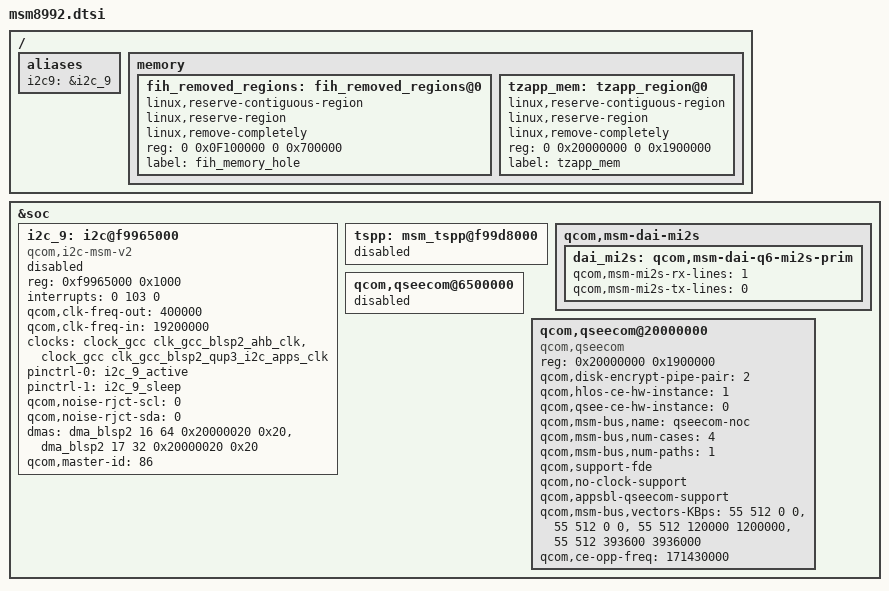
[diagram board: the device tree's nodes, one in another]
/* Copyright (c) 2013-2016, The Linux Foundation. All rights reserved.
 *
 * This program is free software; you can redistribute it and/or modify
 * it under the terms of the GNU General Public License version 2 and
 * only version 2 as published by the Free Software Foundation.
 *
 * This program is distributed in the hope that it will be useful,
 * but WITHOUT ANY WARRANTY; without even the implied warranty of
 * MERCHANTABILITY or FITNESS FOR A PARTICULAR PURPOSE.  See the
 * GNU General Public License for more details.
 */

/ {
	aliases {
		i2c9 = &i2c_9;
	};

	memory {
		fih_removed_regions: fih_removed_regions@0 {
			linux,reserve-contiguous-region;
			linux,reserve-region;
			linux,remove-completely;
			reg = <0 0x0F100000 0 0x700000>;
			label = "fih_memory_hole";
		};

		tzapp_mem: tzapp_region@0 {
			linux,reserve-contiguous-region;
			linux,reserve-region;
			linux,remove-completely;
			reg = <0 0x20000000 0 0x1900000>;
			label = "tzapp_mem";
		};
	};
};

&soc {
	i2c_9: i2c@f9965000 { /* BLSP9 QUP2 */
		compatible = "qcom,i2c-msm-v2";
		#address-cells = <1>;
		#size-cells = <0>;
		status = "disabled";
		reg-names = "qup_phys_addr";
		reg = <0xf9965000 0x1000>;
		interrupt-names = "qup_irq";
		interrupts = <0 103 0>;
		qcom,clk-freq-out = <400000>;
		qcom,clk-freq-in  = <19200000>;
		clock-names = "iface_clk", "core_clk";
		clocks = <&clock_gcc clk_gcc_blsp2_ahb_clk>,
			 <&clock_gcc clk_gcc_blsp2_qup3_i2c_apps_clk>;

		pinctrl-names = "i2c_active", "i2c_sleep";
		pinctrl-0 = <&i2c_9_active>;
		pinctrl-1 = <&i2c_9_sleep>;
		qcom,noise-rjct-scl = <0>;
		qcom,noise-rjct-sda = <0>;
		dmas = <&dma_blsp2 16 64 0x20000020 0x20>,
			<&dma_blsp2 17 32 0x20000020 0x20>;
		dma-names = "tx", "rx";
		qcom,master-id = <86>;
	};

	tspp: msm_tspp@f99d8000 {
		status = "disabled";
	};

	qcom,msm-dai-mi2s {
		dai_mi2s: qcom,msm-dai-q6-mi2s-prim {
			qcom,msm-mi2s-rx-lines = <1>;
			qcom,msm-mi2s-tx-lines = <0>;
		};
	};

	qcom,qseecom@6500000 {
		status = "disabled";
	};

	qcom,qseecom@20000000 {
		compatible = "qcom,qseecom";
		reg = <0x20000000 0x1900000>;
		reg-names = "secapp-region";
		qcom,disk-encrypt-pipe-pair = <2>;
		qcom,hlos-ce-hw-instance = <1>;
		qcom,qsee-ce-hw-instance = <0>;
		qcom,msm-bus,name = "qseecom-noc";
		qcom,msm-bus,num-cases = <4>;
		qcom,msm-bus,num-paths = <1>;
		qcom,support-fde;
		qcom,no-clock-support;
		qcom,appsbl-qseecom-support;
		qcom,msm-bus,vectors-KBps =
				<55 512 0 0>,
				<55 512 0 0>,
				<55 512 120000 1200000>,
				<55 512 393600 3936000>;
		qcom,ce-opp-freq = <171430000>;
	};
};
